AUTOSAR XML (schema 4-2-2)
package /ComponentTypes
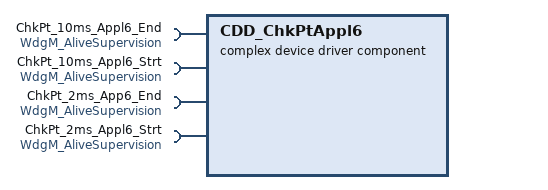
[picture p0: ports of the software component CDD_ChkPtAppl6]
  complex device driver sw component type CDD_ChkPtAppl6
    4 x require port, all with client-com-spec=CheckpointReached, required-interface=WdgM_AliveSupervision:
      ChkPt_10ms_Appl6_End
      ChkPt_10ms_Appl6_Strt
      ChkPt_2ms_App6_End
      ChkPt_2ms_Appl6_Strt
    behavior CDD_ChkPtAppl6_InternalBehavior
      4 x timing event:
        TMT_ChkPt_10msAppl6End: start-on-event=ChkPt_10msAppl6End, period=0.01
        TMT_ChkPt_10msAppl6Strt: start-on-event=ChkPt_10msAppl6Strt, period=0.01
        TMT_ChkPt_2msAppl6End: start-on-event=ChkPt_2msAppl6End, period=0.002
        TMT_ChkPt_2msAppl6Strt: start-on-event=ChkPt_2msAppl6Strt, period=0.002
      4 x runnable:
        ChkPt_10msAppl6End
          sync call SC_ChkPt_10ms_Appl6_End_CheckpointReached: operation=ChkPt_10ms_Appl6_End.CheckpointReached, timeout=0
        ChkPt_10msAppl6Strt
          sync call SC_ChkPt_10ms_Appl6_Strt_CheckpointReached: operation=ChkPt_10ms_Appl6_Strt.CheckpointReached, timeout=0
        ChkPt_2msAppl6End
          sync call SC_ChkPt_2ms_App6_End_CheckpointReached: operation=ChkPt_2ms_App6_End.CheckpointReached, timeout=0
        ChkPt_2msAppl6Strt
          sync call SC_ChkPt_2ms_Appl6_Strt_CheckpointReached: operation=ChkPt_2ms_Appl6_Strt.CheckpointReached, timeout=0
  swc implementation CDD_ChkPtAppl6_Implementation: behavior=CDD_ChkPtAppl6_InternalBehavior
    code-descriptors:
      code Default: artifact-descriptors=autosar-engineering-object={short-label=Default, category=SWSRC}
